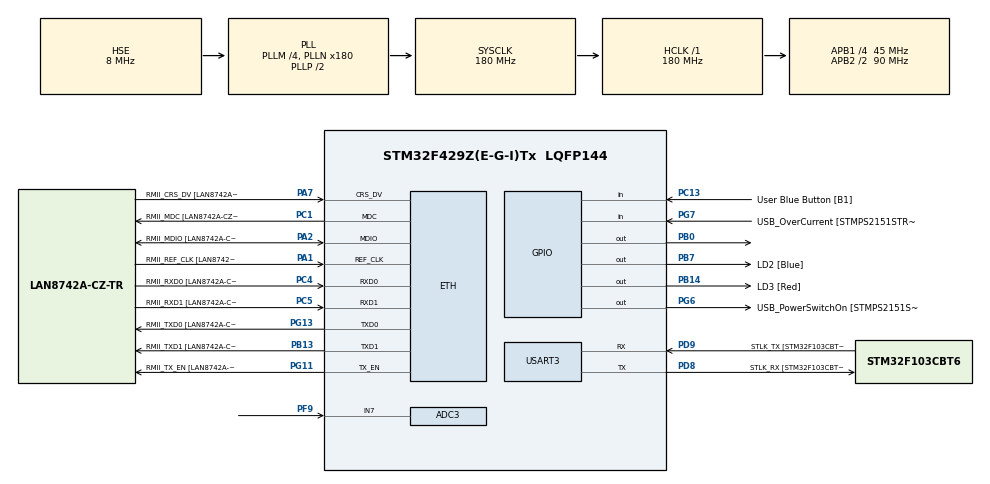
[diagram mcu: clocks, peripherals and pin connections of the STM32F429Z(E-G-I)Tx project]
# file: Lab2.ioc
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ADC3.Channel-0\#ChannelRegularConversion=ADC_CHANNEL_7
ADC3.ContinuousConvMode=ENABLE
ADC3.NbrOfConversionFlag=1
ADC3.Rank-0\#ChannelRegularConversion=1
ADC3.SamplingTime-0\#ChannelRegularConversion=ADC_SAMPLETIME_56CYCLES
ETH.MediaInterface=ETH_MEDIA_INTERFACE_RMII
ETH.PHY_DUPLEX_STATUS=0x0010
ETH.PHY_MICR=0x1D
ETH.PHY_MISR=0x1E
ETH.PHY_MISR_LINK_INT_EN=0x0010
ETH.PHY_Name=LAN8742A_PHY_ADDRESS
ETH.PHY_RESET_DELAY=0x00000FFF
ETH.PHY_SPEED_STATUS=0x0004
ETH.PHY_SR=0x1F
ETH.PhyAddress=0
ETH.RxMode=ETH_RXPOLLING_MODE
LWIP.GATEWAY_ADDRESS=192.168.000.001
LWIP.IP_ADDRESS=192.168.000.010
LWIP.LWIP_DHCP=0
LWIP.LWIP_HTTPD=1
LWIP.LWIP_NETIF_LINK_CALLBACK=1
LWIP.LWIP_UDP=1
LWIP.MEMP_NUM_PBUF=10
LWIP.MEMP_NUM_RAW_PCB=4
LWIP.MEMP_NUM_TCP_PCB=10
LWIP.MEMP_NUM_TCP_PCB_LISTEN=10
LWIP.MEMP_NUM_TCP_SEG=12
LWIP.MEMP_NUM_UDP_PCB=6
LWIP.MEM_SIZE=10240
LWIP.NETMASK_ADDRESS=255.255.255.000
LWIP.NO_SYS_NO_TIMERS=0
LWIP.PBUF_POOL_BUFSIZE=1524
LWIP.PBUF_POOL_SIZE=12
LWIP.TCP_MSS=1460
LWIP.TCP_QUEUE_OOSEQ=0
LWIP.TCP_SND_BUF=5840
LWIP.TCP_SND_QUEUELEN=8
LWIP.TCP_WND=2920
LWIP.Version=v1.5.0_RC0_20160211_Cube
Mcu.Family=STM32F4
Mcu.Name=STM32F429Z(E-G-I)Tx
Mcu.Package=LQFP144
NVIC.ETH_IRQn=true\:7\:0\:true\:false\:true
NVIC.PriorityGroup=NVIC_PRIORITYGROUP_4
PA1.GPIO_Label=RMII_REF_CLK [LAN8742A-CZ-TR_REFCLK0]
PA1.Mode=RMII
PA1.Signal=ETH_REF_CLK
PA10.GPIO_Label=USB_ID
PA10.Signal=USB_OTG_FS_ID
PA11.GPIO_Label=USB_DM
PA11.Signal=USB_OTG_FS_DM
PA12.GPIO_Label=USB_DP
PA12.Signal=USB_OTG_FS_DP
PA13.GPIO_Label=TMS
PA13.Mode=Serial_Wire
PA13.Signal=SYS_JTMS-SWDIO
PA14.GPIO_Label=TCK
PA14.Mode=Serial_Wire
PA14.Signal=SYS_JTCK-SWCLK
PA2.GPIO_Label=RMII_MDIO [LAN8742A-CZ-TR_MDIO]
PA2.Mode=RMII
PA2.Signal=ETH_MDIO
PA7.GPIO_Label=RMII_CRS_DV [LAN8742A-CZ-TR_CRS_DV]
PA7.Mode=RMII
PA7.Signal=ETH_CRS_DV
PA8.GPIO_Label=USB_SOF [TP1]
PA8.Signal=USB_OTG_FS_SOF
PA9.GPIO_Label=USB_VBUS
PA9.Signal=USB_OTG_FS_VBUS
PB0.Signal=GPIO_Output
PB13.GPIO_Label=RMII_TXD1 [LAN8742A-CZ-TR_TXD1]
PB13.Mode=RMII
PB13.Signal=ETH_TXD1
PB14.GPIO_Label=LD3 [Red]
PB14.Signal=GPIO_Output
PB7.GPIO_Label=LD2 [Blue]
PB7.Signal=GPIO_Output
PC1.GPIO_Label=RMII_MDC [LAN8742A-CZ-TR_MDC]
PC1.Mode=RMII
PC1.Signal=ETH_MDC
PC13.GPIO_Label=User Blue Button [B1]
PC13.Signal=GPIO_Input
PC14/OSC32_IN.Mode=LSE-External-Oscillator
PC14/OSC32_IN.Signal=RCC_OSC32_IN
PC15/OSC32_OUT.Mode=LSE-External-Oscillator
PC15/OSC32_OUT.Signal=RCC_OSC32_OUT
PC4.GPIO_Label=RMII_RXD0 [LAN8742A-CZ-TR_RXD0]
PC4.Mode=RMII
PC4.Signal=ETH_RXD0
PC5.GPIO_Label=RMII_RXD1 [LAN8742A-CZ-TR_RXD1]
PC5.Mode=RMII
PC5.Signal=ETH_RXD1
PD8.GPIO_Label=STLK_RX [STM32F103CBT6_PA3]
PD8.Mode=Asynchronous
PD8.Signal=USART3_TX
PD9.GPIO_Label=STLK_TX [STM32F103CBT6_PA2]
PD9.Mode=Asynchronous
PD9.Signal=USART3_RX
PF9.Mode=IN7
PF9.Signal=ADC3_IN7
PG11.GPIO_Label=RMII_TX_EN [LAN8742A-CZ-TR_TXEN]
PG11.Mode=RMII
PG11.Signal=ETH_TX_EN
PG13.GPIO_Label=RMII_TXD0 [LAN8742A-CZ-TR_TXD0]
PG13.Mode=RMII
PG13.Signal=ETH_TXD0
PG6.GPIO_Label=USB_PowerSwitchOn [STMPS2151STR_EN]
PG6.Signal=GPIO_Output
PG7.GPIO_Label=USB_OverCurrent [STMPS2151STR_FAULT]
PG7.Signal=GPIO_Input
PH0/OSC_IN.GPIO_Label=MCO [STM32F103CBT6_PA8]
PH0/OSC_IN.Mode=HSE-External-Oscillator
PH0/OSC_IN.Signal=RCC_OSC_IN
PH1/OSC_OUT.Mode=HSE-External-Oscillator
PH1/OSC_OUT.Signal=RCC_OSC_OUT
ProjectManager.HeapSize=0x200
ProjectManager.StackSize=0x400
ProjectManager.TargetToolchain=EWARM
RCC.48MHZClocksFreq_Value=90000000
RCC.AHBFreq_Value=180000000
RCC.APB1CLKDivider=RCC_HCLK_DIV4
RCC.APB1Freq_Value=45000000
RCC.APB1TimFreq_Value=90000000
RCC.APB2CLKDivider=RCC_HCLK_DIV2
RCC.APB2Freq_Value=90000000
RCC.APB2TimFreq_Value=180000000
RCC.CortexFreq_Value=180000000
RCC.HCLKFreq_Value=180000000
RCC.HSE_VALUE=8000000
RCC.HSI_VALUE=8000000
RCC.PLLM=4
RCC.PLLMUL=RCC_PLL_MUL9
RCC.PLLN=180
RCC.PLLSourceVirtual=RCC_PLLSOURCE_HSE
RCC.PRESCALERUSB=RCC_USBCLKSOURCE_PLL_DIV1_5
RCC.SYSCLKFreq_VALUE=180000000
RCC.SYSCLKSource=RCC_SYSCLKSOURCE_PLLCLK
RCC.SYSCLKSourceVirtual=RCC_SYSCLKSOURCE_PLLCLK
RCC.USBFreq_Value=48000000
RCC.VCOOutputFreq_Value=360000000
VP_LWIP_VS_Enabled.Mode=Enabled
board=NUCLEO-F429ZI

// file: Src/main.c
/**
  ******************************************************************************
  * File Name          : main.c
  * Description        : Main program body
  ******************************************************************************
  *
  * COPYRIGHT(c) 2016 STMicroelectronics
  *
  * Redistribution and use in source and binary forms, with or without modification,
  * are permitted provided that the following conditions are met:
  *   1. Redistributions of source code must retain the above copyright notice,
  *      this list of conditions and the following disclaimer.
  *   2. Redistributions in binary form must reproduce the above copyright notice,
  *      this list of conditions and the following disclaimer in the documentation
  *      and/or other materials provided with the distribution.
  *   3. Neither the name of STMicroelectronics nor the names of its contributors
  *      may be used to endorse or promote products derived from this software
  *      without specific prior written permission.
  *
  * THIS SOFTWARE IS PROVIDED BY THE COPYRIGHT HOLDERS AND CONTRIBUTORS "AS IS"
  * AND ANY EXPRESS OR IMPLIED WARRANTIES, INCLUDING, BUT NOT LIMITED TO, THE
  * IMPLIED WARRANTIES OF MERCHANTABILITY AND FITNESS FOR A PARTICULAR PURPOSE ARE
  * DISCLAIMED. IN NO EVENT SHALL THE COPYRIGHT HOLDER OR CONTRIBUTORS BE LIABLE
  * FOR ANY DIRECT, INDIRECT, INCIDENTAL, SPECIAL, EXEMPLARY, OR CONSEQUENTIAL
  * DAMAGES (INCLUDING, BUT NOT LIMITED TO, PROCUREMENT OF SUBSTITUTE GOODS OR
  * SERVICES; LOSS OF USE, DATA, OR PROFITS; OR BUSINESS INTERRUPTION) HOWEVER
  * CAUSED AND ON ANY THEORY OF LIABILITY, WHETHER IN CONTRACT, STRICT LIABILITY,
  * OR TORT (INCLUDING NEGLIGENCE OR OTHERWISE) ARISING IN ANY WAY OUT OF THE USE
  * OF THIS SOFTWARE, EVEN IF ADVISED OF THE POSSIBILITY OF SUCH DAMAGE.
  *
  ******************************************************************************
  */
#include "stm32f4xx_hal.h"
#include "adc.h"
#include "lwip.h"
#include "usart.h"
#include "gpio.h"

/* USER CODE BEGIN Includes */
#include "http_cgi_ssi.h"
#include "app_ethernet.h"
/* USER CODE END Includes */

/* USER CODE BEGIN PV */
/* Private variables ---------------------------------------------------------*/

/* USER CODE END PV */

void SystemClock_Config(void);
void Error_Handler(void);

/* USER CODE BEGIN PFP */
/* Private function prototypes -----------------------------------------------*/

/* USER CODE END PFP */

int main(void)
{

  /* MCU Configuration----------------------------------------------------------*/

  /* Reset of all peripherals, Initializes the Flash interface and the Systick. */
  HAL_Init();

  /* Configure the system clock */
  SystemClock_Config();

  /* Initialize all configured peripherals */
  MX_GPIO_Init();
  MX_USART3_UART_Init();
  MX_LWIP_Init();
  MX_ADC3_Init();

  /* USER CODE BEGIN 2 */

  /* Http webserver Init */
  http_server_init();

  /* Notify user about the network interface config */
  User_notification(&gnetif);
  /* USER CODE END 2 */

  /* Infinite loop */
  while (1)
  {

  /* USER CODE BEGIN 3 */
    /* Read a received packet from the Ethernet buffers and send it
       to the lwIP for handling */
    ethernetif_input(&gnetif);

    /* Handle timeouts */
    sys_check_timeouts();
  }
  /* USER CODE END 3 */

}

/** System Clock Configuration
*/
void SystemClock_Config(void)
{

  RCC_OscInitTypeDef RCC_OscInitStruct;
  RCC_ClkInitTypeDef RCC_ClkInitStruct;

  __HAL_RCC_PWR_CLK_ENABLE();

  __HAL_PWR_VOLTAGESCALING_CONFIG(PWR_REGULATOR_VOLTAGE_SCALE1);

  RCC_OscInitStruct.OscillatorType = RCC_OSCILLATORTYPE_HSE;
  RCC_OscInitStruct.HSEState = RCC_HSE_ON;
  RCC_OscInitStruct.PLL.PLLState = RCC_PLL_ON;
  RCC_OscInitStruct.PLL.PLLSource = RCC_PLLSOURCE_HSE;
  RCC_OscInitStruct.PLL.PLLM = 4;
  RCC_OscInitStruct.PLL.PLLN = 180;
  RCC_OscInitStruct.PLL.PLLP = RCC_PLLP_DIV2;
  RCC_OscInitStruct.PLL.PLLQ = 4;
  if (HAL_RCC_OscConfig(&RCC_OscInitStruct) != HAL_OK)
  {
    Error_Handler();
  }

  if (HAL_PWREx_EnableOverDrive() != HAL_OK)
  {
    Error_Handler();
  }

  RCC_ClkInitStruct.ClockType = RCC_CLOCKTYPE_HCLK|RCC_CLOCKTYPE_SYSCLK
                              |RCC_CLOCKTYPE_PCLK1|RCC_CLOCKTYPE_PCLK2;
  RCC_ClkInitStruct.SYSCLKSource = RCC_SYSCLKSOURCE_PLLCLK;
  RCC_ClkInitStruct.AHBCLKDivider = RCC_SYSCLK_DIV1;
  RCC_ClkInitStruct.APB1CLKDivider = RCC_HCLK_DIV4;
  RCC_ClkInitStruct.APB2CLKDivider = RCC_HCLK_DIV2;
  if (HAL_RCC_ClockConfig(&RCC_ClkInitStruct, FLASH_LATENCY_5) != HAL_OK)
  {
    Error_Handler();
  }

  HAL_SYSTICK_Config(HAL_RCC_GetHCLKFreq()/1000);

  HAL_SYSTICK_CLKSourceConfig(SYSTICK_CLKSOURCE_HCLK);

  /* SysTick_IRQn interrupt configuration */
  HAL_NVIC_SetPriority(SysTick_IRQn, 0, 0);
}

void Error_Handler(void)
{
  while(1)
  {
  }
}

/************************ (C) COPYRIGHT STMicroelectronics *****END OF FILE****/
